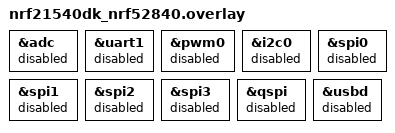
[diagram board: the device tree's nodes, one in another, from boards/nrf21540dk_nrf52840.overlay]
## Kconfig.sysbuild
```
#
# Copyright (c) 2024 Nordic Semiconductor ASA
#
# SPDX-License-Identifier: LicenseRef-Nordic-5-Clause
#

source "share/sysbuild/Kconfig"

config NRF_DEFAULT_IPC_RADIO
	default y
```

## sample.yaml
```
sample:
  description: Test CoAP communication in Thread network
  name: OpenThreadThread CoAP Client

tests:
  sample.openthread.coap_client:
    sysbuild: true
    build_only: true
    tags:
      - ci_build
      - sysbuild
      - ci_samples_openthread
    platform_allow:
      - nrf52840dk/nrf52840
      - nrf21540dk/nrf52840
      - nrf5340dk/nrf5340/cpuapp
    integration_platforms:
      - nrf52840dk/nrf52840
      - nrf21540dk/nrf52840
      - nrf5340dk/nrf5340/cpuapp
  sample.openthread.coap_client.ftd:
    sysbuild: true
    build_only: true
    tags:
      - ci_build
      - sysbuild
      - ci_samples_openthread
    platform_allow:
      - nrf52840dk/nrf52840
      - nrf21540dk/nrf52840
      - nrf5340dk/nrf5340/cpuapp
    extra_args: >
      coap_client_SNIPPET="ci;logging"
    integration_platforms:
      - nrf52840dk/nrf52840
      - nrf21540dk/nrf52840
      - nrf5340dk/nrf5340/cpuapp
  sample.openthread.coap_client.mtd:
    sysbuild: true
    build_only: true
    tags:
      - ci_build
      - sysbuild
      - ci_samples_openthread
    platform_allow:
      - nrf52840dk/nrf52840
      - nrf21540dk/nrf52840
      - nrf5340dk/nrf5340/cpuapp
    extra_args: >
      coap_client_SNIPPET="ci;logging;mtd"
    integration_platforms:
      - nrf52840dk/nrf52840
      - nrf21540dk/nrf52840
      - nrf5340dk/nrf5340/cpuapp
  sample.openthread.coap_client.mtd.multiprotocol_ble:
    sysbuild: true
    build_only: true
    tags:
      - ci_build
      - sysbuild
      - ci_samples_openthread
    platform_allow:
      - nrf52840dk/nrf52840
      - nrf21540dk/nrf52840
      - nrf5340dk/nrf5340/cpuapp
    extra_args:
      - coap_client_SNIPPET="ci;logging;mtd;multiprotocol_ble"
      - FILE_SUFFIX=ble
    integration_platforms:
      - nrf52840dk/nrf52840
      - nrf21540dk/nrf52840
      - nrf5340dk/nrf5340/cpuapp
```

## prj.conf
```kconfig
#
# Copyright (c) 2020 Nordic Semiconductor
#
# SPDX-License-Identifier: LicenseRef-Nordic-5-Clause
#

# nRF board library
CONFIG_DK_LIBRARY=y

# Enable CoAP utils and CoAP protocol
CONFIG_COAP=y
CONFIG_COAP_UTILS=y

# Generic networking options
CONFIG_NETWORKING=y

# L2 OpenThread enabling
CONFIG_NET_L2_OPENTHREAD=y

# Network shell
CONFIG_SHELL=y
CONFIG_OPENTHREAD_SHELL=y
CONFIG_SHELL_ARGC_MAX=26
CONFIG_SHELL_CMD_BUFF_SIZE=416

# Increase Settings storage size
CONFIG_PM_PARTITION_SIZE_SETTINGS_STORAGE=0x8000

# Network sockets
CONFIG_NET_SOCKETS=y
CONFIG_NET_SOCKETS_POLL_MAX=4

# Same network Master Key for client and server
CONFIG_OPENTHREAD_NETWORKKEY="00:11:22:33:44:55:66:77:88:99:aa:bb:cc:dd:ee:ff"

CONFIG_MBEDTLS_SHA1_C=n
CONFIG_FPU=y

# Increase main stack size to meet networking requirements
CONFIG_MAIN_STACK_SIZE=4096
```

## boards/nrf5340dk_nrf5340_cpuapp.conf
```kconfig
#
# Copyright (c) 2021 Nordic Semiconductor
#
# SPDX-License-Identifier: LicenseRef-Nordic-5-Clause
#

# Default PRNG entropy for nRF53 Series devices is CSPRNG CC312
# which for that purpose is too slow yet
# Use Xoshiro128++ as PRNG
CONFIG_XOSHIRO_RANDOM_GENERATOR=y
```

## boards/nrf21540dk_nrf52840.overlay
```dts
/* Copyright (c) 2020 Nordic Semiconductor ASA
 *
 * SPDX-License-Identifier: LicenseRef-Nordic-5-Clause
 */

/* Default Zephyr configuration already provides GPIO support for FEM. */

&adc {
	status = "disabled";
};
&uart1 {
	status = "disabled";
};
&pwm0 {
	status = "disabled";
};
&i2c0 {
	status = "disabled";
};
&spi0 {
	status = "disabled";
};
&spi1 {
	status = "disabled";
};
&spi2 {
	status = "disabled";
};
&spi3 {
	status = "disabled";
};
&qspi {
	status = "disabled";
};
&usbd {
	status = "disabled";
};
```

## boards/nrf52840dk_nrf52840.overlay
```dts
/* Copyright (c) 2020 Nordic Semiconductor ASA
 *
 * SPDX-License-Identifier: LicenseRef-Nordic-5-Clause
 */

&adc {
	status = "disabled";
};
&uart1 {
	status = "disabled";
};
&pwm0 {
	status = "disabled";
};
&i2c0 {
	status = "disabled";
};
&spi0 {
	status = "disabled";
};
&spi1 {
	status = "disabled";
};
&spi2 {
	status = "disabled";
};
&spi3 {
	status = "disabled";
};
&qspi {
	status = "disabled";
};
&usbd {
	status = "disabled";
};
```

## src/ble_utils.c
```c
/*
 * Copyright (c) 2020 Nordic Semiconductor ASA
 *
 * SPDX-License-Identifier: LicenseRef-Nordic-5-Clause
 */

#include <zephyr/kernel.h>
#include <zephyr/bluetooth/gatt.h>
#include <zephyr/bluetooth/hci.h>
#include <zephyr/bluetooth/uuid.h>
#include <zephyr/logging/log.h>
#include <zephyr/settings/settings.h>

#include "ble_utils.h"

LOG_MODULE_REGISTER(ble_utils, CONFIG_BLE_UTILS_LOG_LEVEL);

#define DEVICE_NAME CONFIG_BT_DEVICE_NAME
#define DEVICE_NAME_LEN (sizeof(DEVICE_NAME) - 1)

static void connected(struct bt_conn *conn, uint8_t err);
static void disconnected(struct bt_conn *conn, uint8_t reason);
static void auth_passkey_display(struct bt_conn *conn, unsigned int passkey);
static void auth_cancel(struct bt_conn *conn);
static void pairing_complete(struct bt_conn *conn, bool bonded);
static void pairing_failed(struct bt_conn *conn, enum bt_security_err reason);
static void __attribute__((unused))
security_changed(struct bt_conn *conn, bt_security_t level,
		 enum bt_security_err err);

static struct bt_conn_auth_cb conn_auth_callbacks = {
	.passkey_display = auth_passkey_display,
	.cancel = auth_cancel,
};

static struct bt_conn_auth_info_cb conn_auth_info_callbacks = {
	.pairing_complete = pairing_complete,
	.pairing_failed = pairing_failed
};

static struct bt_conn_cb conn_callbacks = {
	.connected = connected,
	.disconnected = disconnected,
	COND_CODE_1(CONFIG_BT_SMP, (.security_changed = security_changed), ())
};

static const struct bt_data ad[] = {
	BT_DATA_BYTES(BT_DATA_FLAGS, (BT_LE_AD_GENERAL | BT_LE_AD_NO_BREDR)),
	BT_DATA(BT_DATA_NAME_COMPLETE, DEVICE_NAME, DEVICE_NAME_LEN),
};

static const struct bt_data sd[] = {
	BT_DATA_BYTES(BT_DATA_UUID128_ALL, BT_UUID_NUS_VAL),
};

static struct k_work on_connect_work;
static struct k_work on_disconnect_work;

static struct bt_conn *current_conn;

static void connected(struct bt_conn *conn, uint8_t err)
{
	if (err) {
		LOG_ERR("Connection failed (err %u)", err);
		return;
	}

	LOG_INF("Connected");
	current_conn = bt_conn_ref(conn);

	k_work_submit(&on_connect_work);
}

static void disconnected(struct bt_conn *conn, uint8_t reason)
{
	LOG_INF("Disconnected (reason %u)", reason);

	if (current_conn) {
		bt_conn_unref(current_conn);
		current_conn = NULL;

		k_work_submit(&on_disconnect_work);
	}
}

static char *ble_addr(struct bt_conn *conn)
{
	static char addr[BT_ADDR_LE_STR_LEN];

	bt_addr_le_to_str(bt_conn_get_dst(conn), addr, sizeof(addr));

	return addr;
}

static void __attribute__((unused))
security_changed(struct bt_conn *conn, bt_security_t level,
		 enum bt_security_err err)
{
	char *addr = ble_addr(conn);

	if (!err) {
		LOG_INF("Security changed: %s level %u", addr, level);
	} else {
		LOG_INF("Security failed: %s level %u err %d", addr, level, err);
	}
}

static void auth_passkey_display(struct bt_conn *conn, unsigned int passkey)
{
	char *addr = ble_addr(conn);

	LOG_INF("Passkey for %s: %06u", addr, passkey);
}

static void auth_cancel(struct bt_conn *conn)
{
	char *addr = ble_addr(conn);

	LOG_INF("Pairing cancelled: %s", addr);
}

static void pairing_complete(struct bt_conn *conn, bool bonded)
{
	char *addr = ble_addr(conn);

	LOG_INF("Pairing completed: %s, bonded: %d", addr, bonded);
}

static void pairing_failed(struct bt_conn *conn, enum bt_security_err reason)
{
	char *addr = ble_addr(conn);

	LOG_INF("Pairing failed conn: %s, reason %d", addr, reason);
}

int ble_utils_init(struct bt_nus_cb *nus_clbs, ble_connection_cb_t on_connect,
		   ble_disconnection_cb_t on_disconnect)
{
	int ret;

	k_work_init(&on_connect_work, on_connect);
	k_work_init(&on_disconnect_work, on_disconnect);

	bt_conn_cb_register(&conn_callbacks);

	if (IS_ENABLED(CONFIG_BT_SMP)) {
		ret = bt_conn_auth_cb_register(&conn_auth_callbacks);
		if (ret) {
			LOG_ERR("Failed to register authorization callbacks.");
			goto end;
		}

		ret = bt_conn_auth_info_cb_register(&conn_auth_info_callbacks);
		if (ret) {
			LOG_ERR("Failed to register authorization info callbacks.");
			goto end;
		}
	}

	ret = bt_enable(NULL);
	if (ret) {
		LOG_ERR("Bluetooth initialization failed (error: %d)", ret);
		goto end;
	}

	LOG_INF("Bluetooth initialized");

	if (IS_ENABLED(CONFIG_SETTINGS)) {
		settings_load();
	}

	ret = bt_nus_init(nus_clbs);
	if (ret) {
		LOG_ERR("Failed to initialize UART service (error: %d)", ret);
		goto end;
	}

	ret = bt_le_adv_start(BT_LE_ADV_CONN_FAST_2, ad, ARRAY_SIZE(ad), sd,
			      ARRAY_SIZE(sd));
	if (ret) {
		LOG_ERR("Advertising failed to start (error: %d)", ret);
		goto end;
	}

end:
	return ret;
}
```

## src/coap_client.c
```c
/*
 * Copyright (c) 2020 Nordic Semiconductor ASA
 *
 * SPDX-License-Identifier: LicenseRef-Nordic-5-Clause
 */

#include <zephyr/kernel.h>
#include <dk_buttons_and_leds.h>
#include <zephyr/logging/log.h>
#include <ram_pwrdn.h>
#include <zephyr/device.h>
#include <zephyr/pm/device.h>

#include "coap_client_utils.h"

#if CONFIG_BT_NUS
#include "ble_utils.h"
#endif

LOG_MODULE_REGISTER(coap_client, CONFIG_COAP_CLIENT_LOG_LEVEL);

#define OT_CONNECTION_LED DK_LED1
#define BLE_CONNECTION_LED DK_LED2
#define MTD_SED_LED DK_LED3

#if CONFIG_BT_NUS

#define COMMAND_REQUEST_UNICAST 'u'
#define COMMAND_REQUEST_MULTICAST 'm'
#define COMMAND_REQUEST_PROVISIONING 'p'

static void on_nus_received(struct bt_conn *conn, const uint8_t *const data, uint16_t len)
{
	LOG_INF("Received data: %c", data[0]);

	switch (*data) {
	case COMMAND_REQUEST_UNICAST:
		coap_client_toggle_one_light();
		break;

	case COMMAND_REQUEST_MULTICAST:
		coap_client_toggle_mesh_lights();
		break;

	case COMMAND_REQUEST_PROVISIONING:
		coap_client_send_provisioning_request();
		break;

	default:
		LOG_WRN("Received invalid data from NUS");
	}
}

static void on_ble_connect(struct k_work *item)
{
	ARG_UNUSED(item);

	dk_set_led_on(BLE_CONNECTION_LED);
}

static void on_ble_disconnect(struct k_work *item)
{
	ARG_UNUSED(item);

	dk_set_led_off(BLE_CONNECTION_LED);
}

#endif /* CONFIG_BT_NUS */

static void on_ot_connect(struct k_work *item)
{
	ARG_UNUSED(item);

	dk_set_led_on(OT_CONNECTION_LED);
}

static void on_ot_disconnect(struct k_work *item)
{
	ARG_UNUSED(item);

	dk_set_led_off(OT_CONNECTION_LED);
}

static void on_mtd_mode_toggle(uint32_t med)
{
#if IS_ENABLED(CONFIG_PM_DEVICE)
	const struct device *cons = DEVICE_DT_GET(DT_CHOSEN(zephyr_console));

	if (!device_is_ready(cons)) {
		return;
	}

	if (med) {
		pm_device_action_run(cons, PM_DEVICE_ACTION_RESUME);
	} else {
		pm_device_action_run(cons, PM_DEVICE_ACTION_SUSPEND);
	}
#endif
	dk_set_led(MTD_SED_LED, med);
}

static void on_button_changed(uint32_t button_state, uint32_t has_changed)
{
	uint32_t buttons = button_state & has_changed;

	if (buttons & DK_BTN1_MSK) {
		coap_client_toggle_one_light();
	}

	if (buttons & DK_BTN2_MSK) {
		coap_client_toggle_mesh_lights();
	}

	if (buttons & DK_BTN3_MSK) {
		coap_client_toggle_minimal_sleepy_end_device();
	}

	if (buttons & DK_BTN4_MSK) {
		coap_client_send_provisioning_request();
	}
}

int main(void)
{
	int ret;

	LOG_INF("Start CoAP-client sample");

	if (IS_ENABLED(CONFIG_RAM_POWER_DOWN_LIBRARY)) {
		power_down_unused_ram();
	}

	ret = dk_buttons_init(on_button_changed);
	if (ret) {
		LOG_ERR("Cannot init buttons (error: %d)", ret);
		return 0;
	}

	ret = dk_leds_init();
	if (ret) {
		LOG_ERR("Cannot init leds, (error: %d)", ret);
		return 0;
	}

#if CONFIG_BT_NUS
	struct bt_nus_cb nus_clbs = {
		.received = on_nus_received,
		.sent = NULL,
	};

	ret = ble_utils_init(&nus_clbs, on_ble_connect, on_ble_disconnect);
	if (ret) {
		LOG_ERR("Cannot init BLE utilities");
		return 0;
	}

#endif /* CONFIG_BT_NUS */

	coap_client_utils_init(on_ot_connect, on_ot_disconnect, on_mtd_mode_toggle);

	return 0;
}
```

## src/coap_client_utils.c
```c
/*
 * Copyright (c) 2020 Nordic Semiconductor ASA
 *
 * SPDX-License-Identifier: LicenseRef-Nordic-5-Clause
 */

#include <zephyr/kernel.h>
#include <coap_server_client_interface.h>
#include <net/coap_utils.h>
#include <zephyr/logging/log.h>
#include <zephyr/net/socket.h>
#include <openthread.h>
#include <openthread/thread.h>

#include "coap_client_utils.h"

LOG_MODULE_REGISTER(coap_client_utils, CONFIG_COAP_CLIENT_UTILS_LOG_LEVEL);

#define RESPONSE_POLL_PERIOD 100

static uint32_t poll_period;

static bool is_connected;

#define COAP_CLIENT_WORKQ_STACK_SIZE 2048
#define COAP_CLIENT_WORKQ_PRIORITY 5

K_THREAD_STACK_DEFINE(coap_client_workq_stack_area, COAP_CLIENT_WORKQ_STACK_SIZE);
static struct k_work_q coap_client_workq;

static struct k_work unicast_light_work;
static struct k_work multicast_light_work;
static struct k_work toggle_MTD_SED_work;
static struct k_work provisioning_work;
static struct k_work on_connect_work;
static struct k_work on_disconnect_work;

mtd_mode_toggle_cb_t on_mtd_mode_toggle;

/* Options supported by the server */
static const char *const light_option[] = { LIGHT_URI_PATH, NULL };
static const char *const provisioning_option[] = { PROVISIONING_URI_PATH,
						   NULL };

/* Thread multicast mesh local address */
static struct sockaddr_in6 multicast_local_addr = {
	.sin6_family = AF_INET6,
	.sin6_port = htons(COAP_PORT),
	.sin6_addr.s6_addr = { 0xff, 0x03, 0x00, 0x00, 0x00, 0x00, 0x00, 0x00,
			       0x00, 0x00, 0x00, 0x00, 0x00, 0x00, 0x00, 0x01 },
	.sin6_scope_id = 0U
};

/* Variable for storing server address acquiring in provisioning handshake */
static char unique_local_addr_str[INET6_ADDRSTRLEN];
static struct sockaddr_in6 unique_local_addr = {
	.sin6_family = AF_INET6,
	.sin6_port = htons(COAP_PORT),
	.sin6_addr.s6_addr = {0, },
	.sin6_scope_id = 0U
};

static bool is_mtd_in_med_mode(otInstance *instance)
{
	return otThreadGetLinkMode(instance).mRxOnWhenIdle;
}

static void poll_period_response_set(void)
{
	otError error;

	otInstance *instance = openthread_get_default_instance();

	if (is_mtd_in_med_mode(instance)) {
		return;
	}

	if (!poll_period) {
		poll_period = otLinkGetPollPeriod(instance);

		error = otLinkSetPollPeriod(instance, RESPONSE_POLL_PERIOD);
		__ASSERT(error == OT_ERROR_NONE, "Failed to set pool period");

		LOG_INF("Poll Period: %dms set", RESPONSE_POLL_PERIOD);
	}
}

static void poll_period_restore(void)
{
	otError error;
	otInstance *instance = openthread_get_default_instance();

	if (is_mtd_in_med_mode(instance)) {
		return;
	}

	if (poll_period) {
		error = otLinkSetPollPeriod(instance, poll_period);
		__ASSERT_NO_MSG(error == OT_ERROR_NONE);

		LOG_INF("Poll Period: %dms restored", poll_period);
		poll_period = 0;
	}
}

static int on_provisioning_reply(const struct coap_packet *response,
				 struct coap_reply *reply,
				 const struct sockaddr *from)
{
	int ret = 0;
	const uint8_t *payload;
	uint16_t payload_size = 0u;

	ARG_UNUSED(reply);
	ARG_UNUSED(from);

	payload = coap_packet_get_payload(response, &payload_size);

	if (payload == NULL ||
	    payload_size != sizeof(unique_local_addr.sin6_addr)) {
		LOG_ERR("Received data is invalid");
		ret = -EINVAL;
		goto exit;
	}

	memcpy(&unique_local_addr.sin6_addr, payload, payload_size);

	if (!zsock_inet_ntop(AF_INET6, payload, unique_local_addr_str,
		       INET6_ADDRSTRLEN)) {
		LOG_ERR("Received data is not IPv6 address: %d", errno);
		ret = -errno;
		goto exit;
	}

	LOG_INF("Received peer address: %s", unique_local_addr_str);

exit:
	if (IS_ENABLED(CONFIG_OPENTHREAD_MTD_SED)) {
		poll_period_restore();
	}

	return ret;
}

static void toggle_one_light(struct k_work *item)
{
	uint8_t payload = (uint8_t)THREAD_COAP_UTILS_LIGHT_CMD_TOGGLE;

	ARG_UNUSED(item);

	if (unique_local_addr.sin6_addr.s6_addr16[0] == 0) {
		LOG_WRN("Peer address not set. Activate 'provisioning' option "
			"on the server side");
		return;
	}

	LOG_INF("Send 'light' request to: %s", unique_local_addr_str);
	coap_send_request(COAP_METHOD_PUT,
			  (const struct sockaddr *)&unique_local_addr,
			  light_option, &payload, sizeof(payload), NULL);
}

static void toggle_mesh_lights(struct k_work *item)
{
	static uint8_t command = (uint8_t)THREAD_COAP_UTILS_LIGHT_CMD_OFF;

	ARG_UNUSED(item);

	command = ((command == THREAD_COAP_UTILS_LIGHT_CMD_OFF) ?
			   THREAD_COAP_UTILS_LIGHT_CMD_ON :
			   THREAD_COAP_UTILS_LIGHT_CMD_OFF);

	LOG_INF("Send multicast mesh 'light' request");
	coap_send_request(COAP_METHOD_PUT,
			  (const struct sockaddr *)&multicast_local_addr,
			  light_option, &command, sizeof(command), NULL);
}

static void send_provisioning_request(struct k_work *item)
{
	ARG_UNUSED(item);

	if (IS_ENABLED(CONFIG_OPENTHREAD_MTD_SED)) {
		/* decrease the polling period for higher responsiveness */
		poll_period_response_set();
	}

	LOG_INF("Send 'provisioning' request");
	coap_send_request(COAP_METHOD_GET,
			  (const struct sockaddr *)&multicast_local_addr,
			  provisioning_option, NULL, 0u, on_provisioning_reply);
}

static void toggle_minimal_sleepy_end_device(struct k_work *item)
{
	otError error;
	otLinkModeConfig mode;
	struct otInstance *instance = openthread_get_default_instance();

	openthread_mutex_lock();
	mode = otThreadGetLinkMode(instance);
	mode.mRxOnWhenIdle = !mode.mRxOnWhenIdle;
	error = otThreadSetLinkMode(instance, mode);
	openthread_mutex_unlock();

	if (error != OT_ERROR_NONE) {
		LOG_ERR("Failed to set MLE link mode configuration");
	} else {
		on_mtd_mode_toggle(mode.mRxOnWhenIdle);
	}
}

static void update_device_state(void)
{
	struct otInstance *instance = openthread_get_default_instance();
	otLinkModeConfig mode = otThreadGetLinkMode(instance);
	on_mtd_mode_toggle(mode.mRxOnWhenIdle);
}

static void on_thread_state_changed(otChangedFlags flags, void *user_data)
{
	struct otInstance *instance = openthread_get_default_instance();

	if (flags & OT_CHANGED_THREAD_ROLE) {
		switch (otThreadGetDeviceRole(instance)) {
		case OT_DEVICE_ROLE_CHILD:
		case OT_DEVICE_ROLE_ROUTER:
		case OT_DEVICE_ROLE_LEADER:
			k_work_submit_to_queue(&coap_client_workq, &on_connect_work);
			is_connected = true;
			break;

		case OT_DEVICE_ROLE_DISABLED:
		case OT_DEVICE_ROLE_DETACHED:
		default:
			k_work_submit_to_queue(&coap_client_workq, &on_disconnect_work);
			is_connected = false;
			break;
		}
	}
}
static struct openthread_state_changed_callback ot_state_chaged_cb = {
	.otCallback = on_thread_state_changed};

static void submit_work_if_connected(struct k_work *work)
{
	if (is_connected) {
		k_work_submit_to_queue(&coap_client_workq, work);
	} else {
		LOG_INF("Connection is broken");
	}
}

void coap_client_utils_init(ot_connection_cb_t on_connect,
			    ot_disconnection_cb_t on_disconnect,
			    mtd_mode_toggle_cb_t on_toggle)
{
	on_mtd_mode_toggle = on_toggle;

	coap_init(AF_INET6, NULL);


	k_work_queue_init(&coap_client_workq);

	k_work_queue_start(&coap_client_workq, coap_client_workq_stack_area,
					K_THREAD_STACK_SIZEOF(coap_client_workq_stack_area),
					COAP_CLIENT_WORKQ_PRIORITY, NULL);

	k_work_init(&on_connect_work, on_connect);
	k_work_init(&on_disconnect_work, on_disconnect);
	k_work_init(&unicast_light_work, toggle_one_light);
	k_work_init(&multicast_light_work, toggle_mesh_lights);
	k_work_init(&provisioning_work, send_provisioning_request);

	openthread_state_changed_callback_register(&ot_state_chaged_cb);
	openthread_run();

	if (IS_ENABLED(CONFIG_OPENTHREAD_MTD_SED)) {
		k_work_init(&toggle_MTD_SED_work,
			    toggle_minimal_sleepy_end_device);
		update_device_state();
	}
}

void coap_client_toggle_one_light(void)
{
	submit_work_if_connected(&unicast_light_work);
}

void coap_client_toggle_mesh_lights(void)
{
	submit_work_if_connected(&multicast_light_work);
}

void coap_client_send_provisioning_request(void)
{
	submit_work_if_connected(&provisioning_work);
}

void coap_client_toggle_minimal_sleepy_end_device(void)
{
	if (IS_ENABLED(CONFIG_OPENTHREAD_MTD_SED)) {
		k_work_submit_to_queue(&coap_client_workq, &toggle_MTD_SED_work);
	}
}
```

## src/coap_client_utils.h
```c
/**
 * @file
 * @defgroup coap_client_utils API for coap_client_* samples
 * @{
 */

/*
 * Copyright (c) 2020 Nordic Semiconductor ASA
 *
 * SPDX-License-Identifier: LicenseRef-Nordic-5-Clause
 */

#ifndef __COAP_CLIENT_UTILS_H__
#define __COAP_CLIENT_UTILS_H__

/** @brief Type indicates function called when OpenThread connection
 *         is established.
 *
 * @param[in] item pointer to work item.
 */
typedef void (*ot_connection_cb_t)(struct k_work *item);

/** @brief Type indicates function called when OpenThread connection is ended.
 *
 * @param[in] item pointer to work item.
 */
typedef void (*ot_disconnection_cb_t)(struct k_work *item);

/** @brief Type indicates function called when the MTD modes are toggled.
 *
 * @param[in] val 1 if the MTD is in MED mode
 *                0 if the MTD is in SED mode
 */
typedef void (*mtd_mode_toggle_cb_t)(uint32_t val);

/** @brief Initialize CoAP client utilities.
 */
void coap_client_utils_init(ot_connection_cb_t on_connect,
			    ot_disconnection_cb_t on_disconnect,
			    mtd_mode_toggle_cb_t on_toggle);

/** @brief Toggle light on the CoAP server node.
 *
 * @note The CoAP server should be paired before to have an affect.
 */
void coap_client_toggle_one_light(void);

/** @brief Toggle lights on all CoAP servers in the network mesh.
 */
void coap_client_toggle_mesh_lights(void);

/** @brief Request for the CoAP server address to pair.
 *
 * @note Enable paring on the CoAP server to get the address.
 */
void coap_client_send_provisioning_request(void);

/** @brief Toggle SED to MED and MED to SED modes.
 *
 * @note Active when the device is working as Minimal Thread Device.
 */
void coap_client_toggle_minimal_sleepy_end_device(void);

#endif

/**
 * @}
 */
```
